# APM32E103xx register map
File version: 1.0
CPU: CM3 r2p1, little endian, no MPU, no FPU, 4 interrupt priority bits
Registers are 32-bit, read-write, reset 0x0 unless marked. A register's access mark holds for its fields unless they carry their own. Offsets are from the block's base; [hi:lo] are bit positions.

## I2C1 — Inter integrated circuit 1
Base 0x40005400
Same registers: I2C2 0x40005800
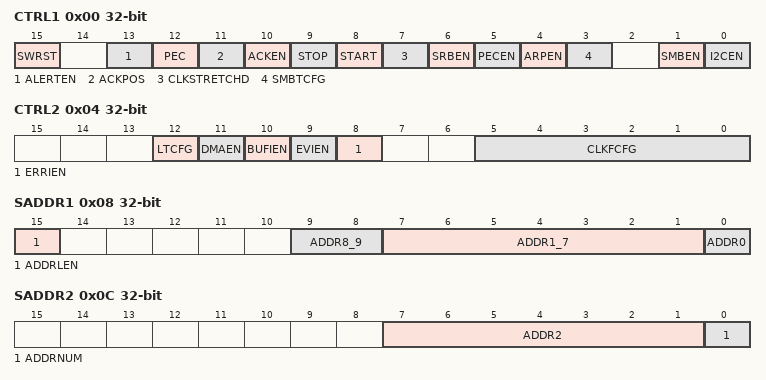
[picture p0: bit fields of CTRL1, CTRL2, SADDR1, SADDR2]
0x00 CTRL1 — Control register 1
  [15] SWRST — Software reset
  [13] ALERTEN — SMBus alert
  [12] PEC — Packet error checking
  [11] ACKPOS — Acknowledge/PEC Position (for data reception)
  [10] ACKEN — Acknowledge enable
  [9] STOP — Stop generation
  [8] START — Start generation
  [7] CLKSTRETCHD — Clock stretching disable (Slave mode)
  [6] SRBEN — General call enable
  [5] PECEN — PEC enable
  [4] ARPEN — ARP enable
  [3] SMBTCFG — SMBus type
  [1] SMBEN — SMBus mode
  [0] I2CEN — Peripheral enable
0x04 CTRL2 — Control register 2
  [12] LTCFG — DMA last transfer
  [11] DMAEN — DMA requests enable
  [10] BUFIEN — Buffer interrupt enable
  [9] EVIEN — Event interrupt enable
  [8] ERRIEN — Error interrupt enable
  [5:0] CLKFCFG — Peripheral clock frequency
0x08 SADDR1 — Own address register 1
  [15] ADDRLEN — Address Length Configure
  [9:8] ADDR8_9 — Interface address
  [7:1] ADDR1_7 — Interface address
  [0] ADDR0 — Interface address
0x0C SADDR2 — Own address register 2
  [7:1] ADDR2 — Interface address
  [0] ADDRNUM — Dual addressing mode enable
0x10 DATA
  [7:0] DATA — 8-bit data register
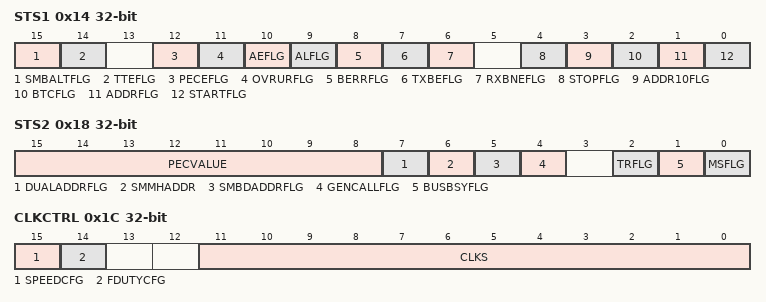
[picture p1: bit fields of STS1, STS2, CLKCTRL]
0x14 STS1 access per field — Status register 1
  [15] SMBALTFLG rw — SMBus alert
  [14] TTEFLG rw — Timeout or Tlow error
  [12] PECEFLG rw — PEC Error in reception
  [11] OVRURFLG rw — Overrun/Underrun
  [10] AEFLG rw — Acknowledge failure
  [9] ALFLG rw — Arbitration lost (master mode)
  [8] BERRFLG rw — Bus error
  [7] TXBEFLG ro — Data register empty (transmitters)
  [6] RXBNEFLG ro — Data register not empty (receivers)
  [4] STOPFLG ro — Stop detection (slave mode)
  [3] ADDR10FLG ro — 10-bit header sent (Master mode)
  [2] BTCFLG ro — Byte transfer finished
  [1] ADDRFLG ro — Address sent (master mode)/matched (slave mode)
  [0] STARTFLG ro — Start bit (Master mode)
0x18 STS2 ro — Status register 2
  [15:8] PECVALUE — acket error checking register
  [7] DUALADDRFLG — Dual flag (Slave mode)
  [6] SMMHADDR — SMBus host header (Slave mode)
  [5] SMBDADDRFLG — SMBus device default address (Slave mode)
  [4] GENCALLFLG — General call address (Slave mode)
  [2] TRFLG — Transmitter/receiver
  [1] BUSBSYFLG — Bus busy
  [0] MSFLG — Master/slave
0x1C CLKCTRL — Clock control register
  [15] SPEEDCFG — I2C master mode selection
  [14] FDUTYCFG — Fast mode duty cycle
  [11:0] CLKS — Clock control register in Fast/Standard mode (Master mode)
0x20 RISETMAX reset 0x2
  [5:0] RISETMAX — Maximum rise time in Fast/Standard mode (Master mode)
0x100 SWITCH reset 0x2 — I2C Switching register
  [0] SWITCH — I2C Switching

## IWDT — Independent watchdog
Base 0x40003000
0x00 KEY wo — Key register (IWDT_KEY)
  [15:0] KEY — Key value
0x04 PSC — Frequency Divider register (IWDT_PSC)
  [2:0] PSC — Prescaler divider
0x08 CNTRLD reset 0xFFF — Reload values register (IWDT_CNTRLD)
  [11:0] CNTRLD — Watchdog counter reload value
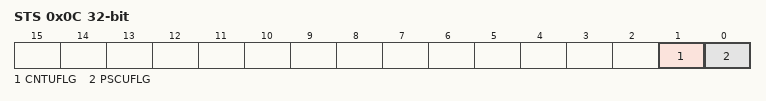
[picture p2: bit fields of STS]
0x0C STS ro — Status register (IWDT_STS)
  [1] CNTUFLG — Watchdog counter reload value update
  [0] PSCUFLG — Watchdog prescaler value update

## WWDT — Window watchdog
Base 0x40002C00
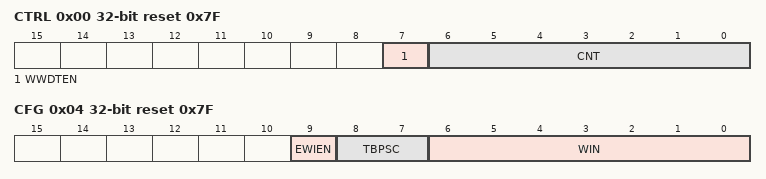
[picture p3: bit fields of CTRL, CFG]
0x00 CTRL reset 0x7F — Control register (WWDT_CTRL)
  [7] WWDTEN — Activation bit
  [6:0] CNT — 7-bit counter (MSB to LSB)
0x04 CFG reset 0x7F — Configuration register (WWDT_CFG)
  [9] EWIEN — Early Wakeup Interrupt
  [8:7] TBPSC — Timer Base
  [6:0] WIN — 7-bit window value
0x08 STS — Status register (WWDT_STS)
  [0] EWIFLG — Early Wakeup Interrupt

## RTC — Real time clock
Base 0x40002800
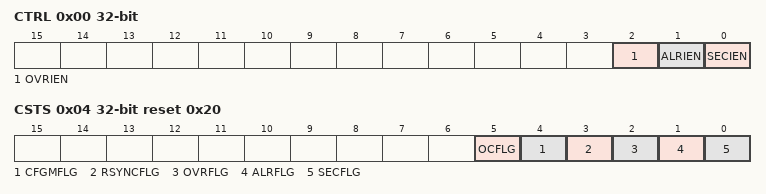
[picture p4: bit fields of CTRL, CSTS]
0x00 CTRL — Control register
  [2] OVRIEN — Overflow interrupt Enable
  [1] ALRIEN — Alarm interrupt Enable
  [0] SECIEN — Second interrupt Enable
0x04 CSTS access per field reset 0x20 — Control and State register
  [5] OCFLG ro — RTC operation OFF
  [4] CFGMFLG rw — Configuration Flag
  [3] RSYNCFLG rw — Registers Synchronized Flag
  [2] OVRFLG rw — Overflow Flag
  [1] ALRFLG rw — Alarm Flag
  [0] SECFLG rw — Second Flag
0x08 PSCRLDH wo — RTC predivision loading register High Bit
  [3:0] PSCRLDH — RTC Prescaler Load Register High
0x0C PSCRLDL wo reset 0x8000 — RTC predivision loading register Low Bit
  [15:0] PSCRLDL — RTC Prescaler Divider Register Low
0x10 PSCH ro — RTC predivider remainder register High Bit
  [3:0] PSCH — RTC prescaler divider register high
0x14 PSCL ro reset 0x8000 — RTC predivider remainder register Low Bit
  [15:0] PSCL — RTC prescaler divider register Low
0x18 CNTH — RTC count register High Bit
  [15:0] CNTH — RTC counter register high
0x1C CNTL — RTC count register Low Bit
  [15:0] CNTL — RTC counter register Low
0x20 ALRH wo reset 0xFFFF — RTC alarm clock register High Bit
  [15:0] ALRH — RTC alarm register high
0x24 ALRL wo reset 0xFFFF — RTC alarm clock register Low Bit
  [15:0] ALRL — RTC alarm register low
